VERSION ""

NS_ :

BS_:

BU_: SG FC

BO_ 257 speedGoat_tx: 1 SG
 SG_ sg_driverSpeaker : 1|1@1- (1,0) [0|1] ""  FC
 SG_ sg_brakeLightEn : 0|1@1- (1,0) [0|1] ""  FC

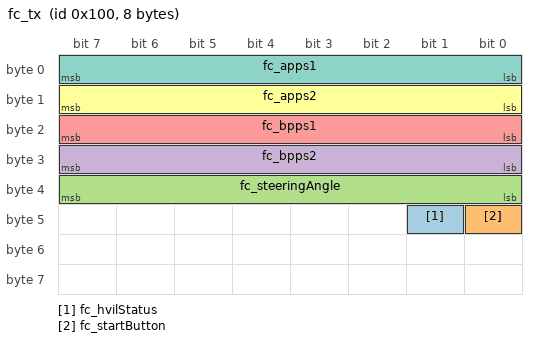
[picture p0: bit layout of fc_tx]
BO_ 256 fc_tx: 8 FC
 SG_ fc_hvilStatus : 41|1@1- (1,0) [0|1] ""  SG
 SG_ fc_startButton : 40|1@1- (1,0) [0|1] ""  SG
 SG_ fc_steeringAngle : 32|8@1+ (0.005,0) [0|1] ""  SG
 SG_ fc_bpps2 : 24|8@1+ (0.005,0) [0|1] ""  SG
 SG_ fc_bpps1 : 16|8@1+ (0.005,0) [0|1] ""  SG
 SG_ fc_apps2 : 8|8@1+ (0.005,0) [0|1] ""  SG
 SG_ fc_apps1 : 0|8@1+ (0.005,0) [0|1] ""  SG
